# ATSAMA5D31 device description
Architecture: CORTEX-A5; Family: SAMA5
Registers are 32-bit, read-write, no defined reset value unless marked. A register's access mark holds for its fields unless they carry their own. Offsets are from the block's base; [hi:lo] are bit positions; {n}, {i} and the like mark numbered series; 'fields as' and 'values as' point back to an identical list.

## BSC — Boot Sequence Controller
Instances: BSC 0xFFFFFE54
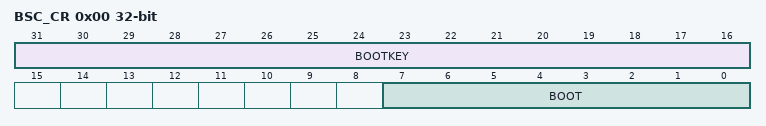
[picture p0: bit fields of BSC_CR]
0x00 BSC_CR — Boot Sequence Configuration Register
  [31:16] BOOTKEY
    0x6683=BSC_KEY (valid key to write BSC_CR register; it needs to be written at the same time as the BOOT field.)
  [7:0] BOOT — Boot media sequence

## FUSE — Fuse Controller
Instances: FUSE 0xFFFFE400
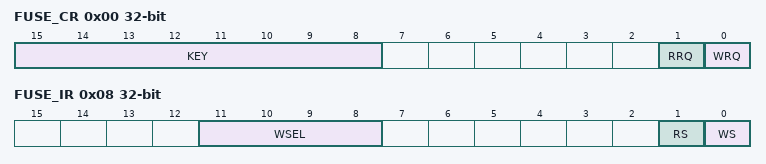
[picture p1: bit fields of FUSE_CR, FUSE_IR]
0x00 FUSE_CR wo — Fuse Control Register
  [15:8] KEY — Key code
    251=VALID (valid key.)
  [1] RRQ — Read Request
  [0] WRQ — Write Request
0x04 FUSE_MR wo — Fuse Mode Register
  [0] MSK — Mask Fuse Status Registers
0x08 FUSE_IR — Fuse Index Register
  [11:8] WSEL — Word Selection
  [1] RS — Read Status
  [0] WS — Write Status
0x0C FUSE_DR — Fuse Data Register
  [31:0] DATA — Data to Program
{0x10+4i} FUSE_SR{i} ro (i=0..7) — Fuse Status Register {i}
  [31:0] FUSE — Fuse Status

## GPBR — General Purpose Backup Register
Instances: GPBR 0xFFFFFE60
{0x0+4i} SYS_GPBR{i} (i=0..3) — General Purpose Backup Register {i}
  [31:0] GPBR_VALUE — Value of GPBR x

## MATRIX — AHB Bus Matrix
Instances: MATRIX 0xFFFFEC00
{0x0+4i} MATRIX_MCFG{i} (i=0..15) — Master Configuration Register {i}
  [2:0] ULBT — Undefined Length Burst Type
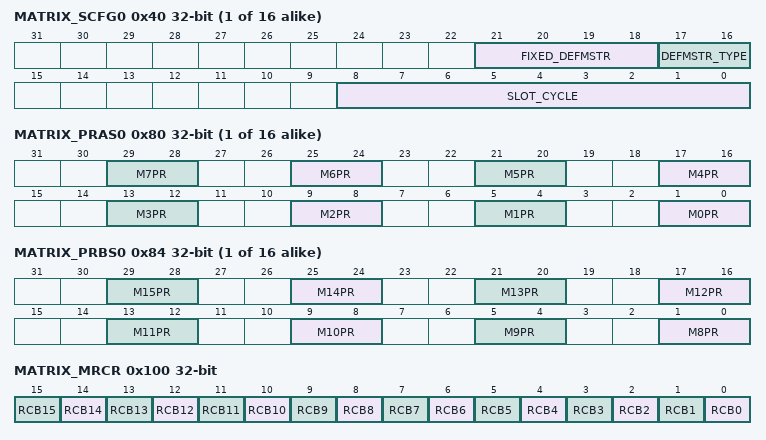
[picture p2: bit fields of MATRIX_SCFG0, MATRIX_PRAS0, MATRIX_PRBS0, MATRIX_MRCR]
{0x40+4i} MATRIX_SCFG{i} (i=0..15) — Slave Configuration Register {i}
  [21:18] FIXED_DEFMSTR — Fixed Default Master
  [17:16] DEFMSTR_TYPE — Default Master Type
  [8:0] SLOT_CYCLE — Maximum Bus Grant Duration for Masters
{0x80+8i} MATRIX_PRAS{i} (i=0..15) — Priority Register A for Slave {i}
  [4n+1:4n] M{n}PR (n=0..7) — Master {n} Priority
{0x84+8i} MATRIX_PRBS{i} (i=0..15) — Priority Register B for Slave {i}
  [4n-31:4n-32] M{n}PR (n=8..15) — Master {n} Priority
0x100 MATRIX_MRCR — Master Remap Control Register
  [n] RCB{n} (n=0..15)
{0x110+4i} MATRIX_SFR{i} (i=0..15) — Special Function Register {i}
  [31:0] SFR — Special Function Register Fields
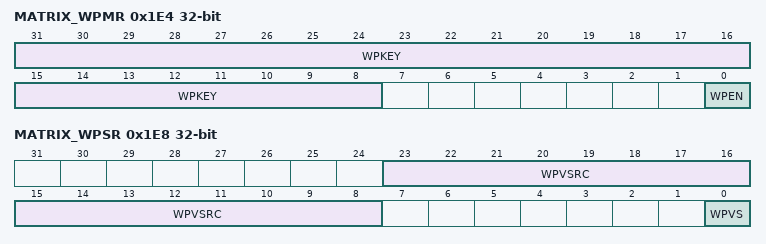
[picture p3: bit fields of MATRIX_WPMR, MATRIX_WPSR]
0x1E4 MATRIX_WPMR — Write Protect Mode Register
  [31:8] WPKEY — Write Protect KEY (Write-only)
  [0] WPEN — Write Protect Enable
0x1E8 MATRIX_WPSR ro — Write Protect Status Register
  [23:8] WPVSRC — Write Protect Violation Source
  [0] WPVS — Write Protect Violation Status

## PIT — Periodic Interval Timer
Instances: PIT 0xFFFFFE30
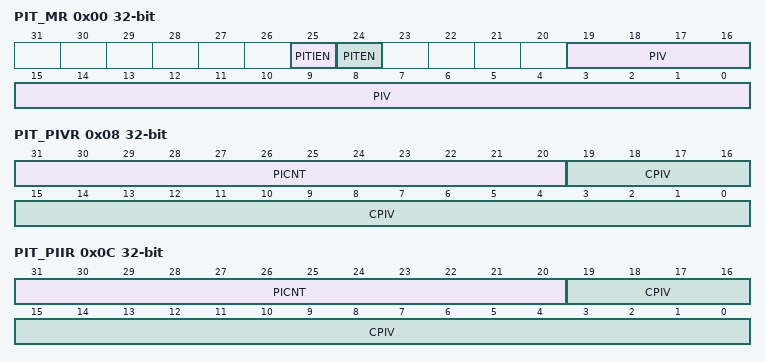
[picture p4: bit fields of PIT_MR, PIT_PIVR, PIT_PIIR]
0x00 PIT_MR — Mode Register
  [25] PITIEN — Periodic Interval Timer Interrupt Enable
  [24] PITEN — Period Interval Timer Enabled
  [19:0] PIV — Periodic Interval Value
0x04 PIT_SR ro — Status Register
  [0] PITS — Periodic Interval Timer Status
0x08 PIT_PIVR ro — Periodic Interval Value Register
  [31:20] PICNT — Periodic Interval Counter
  [19:0] CPIV — Current Periodic Interval Value
0x0C PIT_PIIR ro — Periodic Interval Image Register
  fields as PIT_PIVR

## RSTC — Reset Controller
Instances: RSTC 0xFFFFFE00
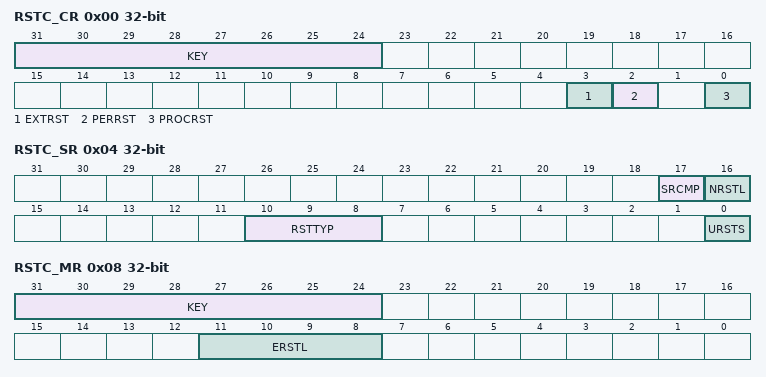
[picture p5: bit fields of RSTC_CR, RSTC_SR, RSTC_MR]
0x00 RSTC_CR wo — Control Register
  [31:24] KEY — Password
  [3] EXTRST — External Reset
  [2] PERRST — Peripheral Reset
  [0] PROCRST — Processor Reset
0x04 RSTC_SR ro — Status Register
  [17] SRCMP — Software Reset Command in Progress
  [16] NRSTL — NRST Pin Level
  [10:8] RSTTYP — Reset Type
  [0] URSTS — User Reset Status
0x08 RSTC_MR — Mode Register
  [31:24] KEY — Password
  [11:8] ERSTL — External Reset Length

## RTC — Real-time Clock
Instances: RTC 0xFFFFFEB0
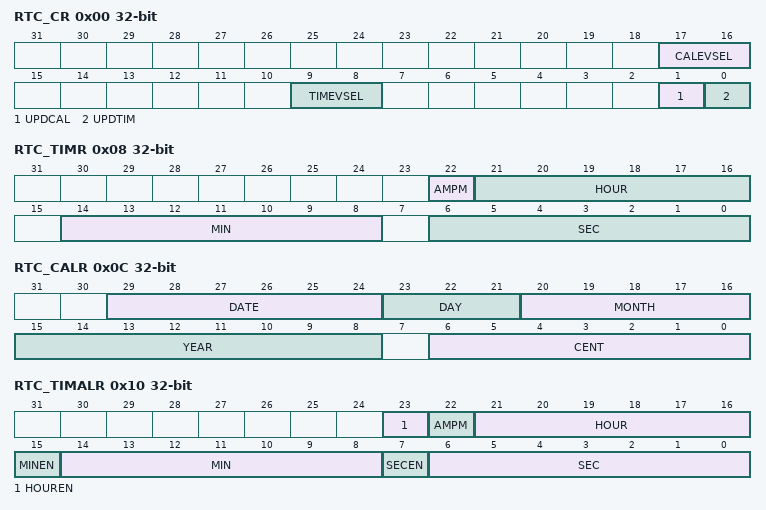
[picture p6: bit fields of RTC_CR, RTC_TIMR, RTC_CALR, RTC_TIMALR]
0x00 RTC_CR — Control Register
  [17:16] CALEVSEL — Calendar Event Selection
    0=WEEK (Week change (every Monday at time 00:00:00)); 1=MONTH (Month change (every 01 of each month at time 00:00:00)); 2=YEAR (Year change (every January 1 at time 00:00:00))
  [9:8] TIMEVSEL — Time Event Selection
    0=MINUTE (Minute change); 1=HOUR (Hour change); 2=MIDNIGHT (Every day at midnight); 3=NOON (Every day at noon)
  [1] UPDCAL — Update Request Calendar Register
  [0] UPDTIM — Update Request Time Register
0x04 RTC_MR — Mode Register
  [0] HRMOD — 12-/24-hour Mode
0x08 RTC_TIMR — Time Register
  [22] AMPM — Ante Meridiem Post Meridiem Indicator
  [21:16] HOUR — Current Hour
  [14:8] MIN — Current Minute
  [6:0] SEC — Current Second
0x0C RTC_CALR — Calendar Register
  [29:24] DATE — Current Day in Current Month
  [23:21] DAY — Current Day in Current Week
  [20:16] MONTH — Current Month
  [15:8] YEAR — Current Year
  [6:0] CENT — Current Century
0x10 RTC_TIMALR — Time Alarm Register
  [23] HOUREN — Hour Alarm Enable
  [22] AMPM — AM/PM Indicator
  [21:16] HOUR — Hour Alarm
  [15] MINEN — Minute Alarm Enable
  [14:8] MIN — Minute Alarm
  [7] SECEN — Second Alarm Enable
  [6:0] SEC — Second Alarm
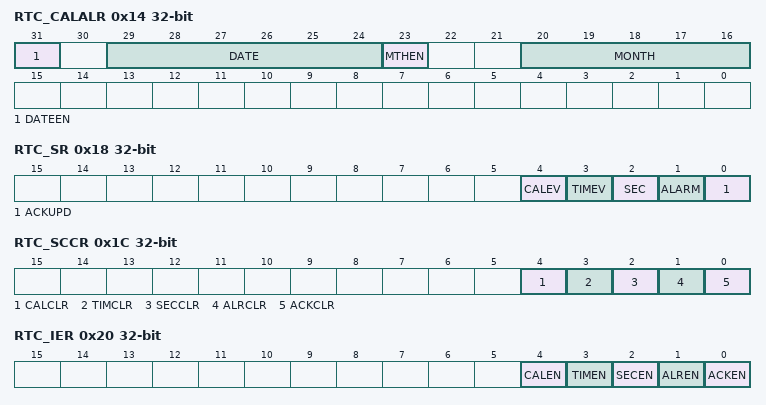
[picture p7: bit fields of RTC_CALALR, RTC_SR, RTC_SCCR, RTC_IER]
0x14 RTC_CALALR — Calendar Alarm Register
  [31] DATEEN — Date Alarm Enable
  [29:24] DATE — Date Alarm
  [23] MTHEN — Month Alarm Enable
  [20:16] MONTH — Month Alarm
0x18 RTC_SR ro — Status Register
  [4] CALEV — Calendar Event
  [3] TIMEV — Time Event
  [2] SEC — Second Event
  [1] ALARM — Alarm Flag
  [0] ACKUPD — Acknowledge for Update
0x1C RTC_SCCR wo — Status Clear Command Register
  [4] CALCLR — Calendar Clear
  [3] TIMCLR — Time Clear
  [2] SECCLR — Second Clear
  [1] ALRCLR — Alarm Clear
  [0] ACKCLR — Acknowledge Clear
0x20 RTC_IER wo — Interrupt Enable Register
  [4] CALEN — Calendar Event Interrupt Enable
  [3] TIMEN — Time Event Interrupt Enable
  [2] SECEN — Second Event Interrupt Enable
  [1] ALREN — Alarm Interrupt Enable
  [0] ACKEN — Acknowledge Update Interrupt Enable
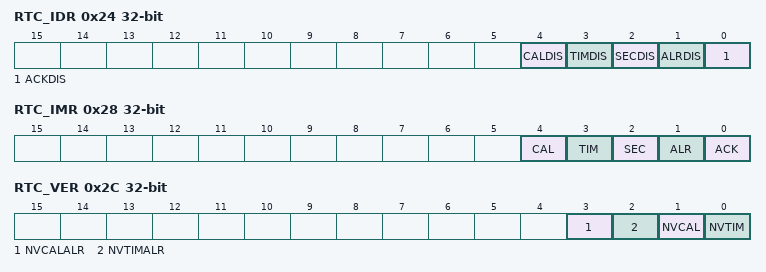
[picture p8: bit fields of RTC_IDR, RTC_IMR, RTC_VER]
0x24 RTC_IDR wo — Interrupt Disable Register
  [4] CALDIS — Calendar Event Interrupt Disable
  [3] TIMDIS — Time Event Interrupt Disable
  [2] SECDIS — Second Event Interrupt Disable
  [1] ALRDIS — Alarm Interrupt Disable
  [0] ACKDIS — Acknowledge Update Interrupt Disable
0x28 RTC_IMR ro — Interrupt Mask Register
  [4] CAL — Calendar Event Interrupt Mask
  [3] TIM — Time Event Interrupt Mask
  [2] SEC — Second Event Interrupt Mask
  [1] ALR — Alarm Interrupt Mask
  [0] ACK — Acknowledge Update Interrupt Mask
0x2C RTC_VER ro — Valid Entry Register
  [3] NVCALALR — Non-valid Calendar Alarm
  [2] NVTIMALR — Non-valid Time Alarm
  [1] NVCAL — Non-valid Calendar
  [0] NVTIM — Non-valid Time
